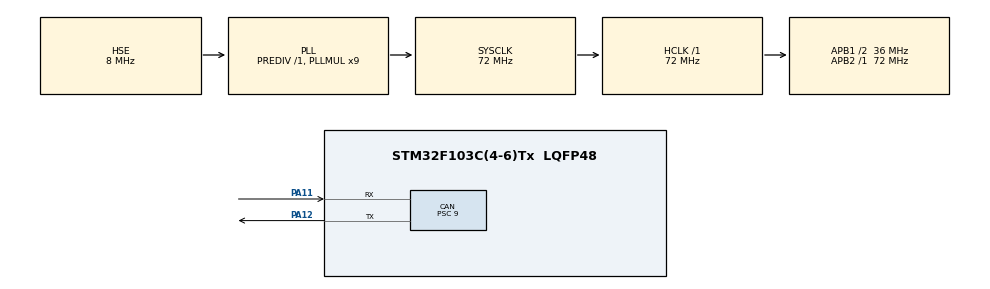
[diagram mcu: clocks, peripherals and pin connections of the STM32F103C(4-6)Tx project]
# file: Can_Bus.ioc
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CAN.ABOM=ENABLE
CAN.BS1=CAN_BS1_5TQ
CAN.BS2=CAN_BS2_2TQ
CAN.CalculateBaudRate=500000
CAN.CalculateTimeBit=2000
CAN.CalculateTimeQuantum=250.0
CAN.NART=ENABLE
CAN.Prescaler=9
Mcu.Family=STM32F1
Mcu.Name=STM32F103C(4-6)Tx
Mcu.Package=LQFP48
NVIC.PriorityGroup=NVIC_PRIORITYGROUP_4
NVIC.USB_LP_CAN1_RX0_IRQn=true\:0\:0\:false\:false\:true\:true\:true\:true
PA11.Mode=CAN_Activate
PA11.Signal=CAN_RX
PA12.Mode=CAN_Activate
PA12.Signal=CAN_TX
PA13.Mode=Serial_Wire
PA13.Signal=SYS_JTMS-SWDIO
PA14.Mode=Serial_Wire
PA14.Signal=SYS_JTCK-SWCLK
PD0-OSC_IN.Mode=HSE-External-Oscillator
PD0-OSC_IN.Signal=RCC_OSC_IN
PD1-OSC_OUT.Mode=HSE-External-Oscillator
PD1-OSC_OUT.Signal=RCC_OSC_OUT
ProjectManager.HeapSize=0x200
ProjectManager.StackSize=0x400
ProjectManager.TargetToolchain=STM32CubeIDE
RCC.AHBFreq_Value=72000000
RCC.APB1CLKDivider=RCC_HCLK_DIV2
RCC.APB1Freq_Value=36000000
RCC.APB1TimFreq_Value=72000000
RCC.APB2Freq_Value=72000000
RCC.APB2TimFreq_Value=72000000
RCC.HCLKFreq_Value=72000000
RCC.PLLMUL=RCC_PLL_MUL9
RCC.PLLSourceVirtual=RCC_PLLSOURCE_HSE
RCC.SYSCLKFreq_VALUE=72000000
RCC.SYSCLKSource=RCC_SYSCLKSOURCE_PLLCLK
RCC.USBFreq_Value=72000000
board=custom

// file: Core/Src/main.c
/* USER CODE BEGIN Header */
/**
  ******************************************************************************
  * @file           : main.c
  * @brief          : Main program body
  ******************************************************************************
  */
/* USER CODE END Header */
#include "main.h"

/* USER CODE BEGIN Includes */
#include "can_lib.h"
/* USER CODE END Includes */

CAN_HandleTypeDef hcan;

void SystemClock_Config(void);
static void MX_GPIO_Init(void);
static void MX_CAN_Init(void);

int main(void)
{

  /* MCU Configuration--------------------------------------------------------*/
  HAL_Init();

  /* Configure the system clock */
  SystemClock_Config();

  /* Initialize all configured peripherals */
  MX_GPIO_Init();
  MX_CAN_Init();

  /* USER CODE BEGIN 2 */
  CAN_Config_Init(&hcan);
  /* USER CODE END 2 */

  /* Infinite loop */
  while (1)
  {

    /* USER CODE BEGIN 3 */
    // Du lieu tu CAN duoc cap nhat tu dong trong callback
    // Xu ly tai day neu can:
    // float acc = can_0x179.acc;
  }
  /* USER CODE END 3 */
}

void SystemClock_Config(void)
{
  RCC_OscInitTypeDef RCC_OscInitStruct = {0};
  RCC_ClkInitTypeDef RCC_ClkInitStruct = {0};

  RCC_OscInitStruct.OscillatorType = RCC_OSCILLATORTYPE_HSE;
  RCC_OscInitStruct.HSEState = RCC_HSE_ON;
  RCC_OscInitStruct.HSEPredivValue = RCC_HSE_PREDIV_DIV1;
  RCC_OscInitStruct.HSIState = RCC_HSI_ON;
  RCC_OscInitStruct.PLL.PLLState = RCC_PLL_ON;
  RCC_OscInitStruct.PLL.PLLSource = RCC_PLLSOURCE_HSE;
  RCC_OscInitStruct.PLL.PLLMUL = RCC_PLL_MUL9;
  if (HAL_RCC_OscConfig(&RCC_OscInitStruct) != HAL_OK)
  {
    Error_Handler();
  }

  RCC_ClkInitStruct.ClockType = RCC_CLOCKTYPE_HCLK|RCC_CLOCKTYPE_SYSCLK
                              |RCC_CLOCKTYPE_PCLK1|RCC_CLOCKTYPE_PCLK2;
  RCC_ClkInitStruct.SYSCLKSource = RCC_SYSCLKSOURCE_PLLCLK;
  RCC_ClkInitStruct.AHBCLKDivider = RCC_SYSCLK_DIV1;
  RCC_ClkInitStruct.APB1CLKDivider = RCC_HCLK_DIV2;
  RCC_ClkInitStruct.APB2CLKDivider = RCC_HCLK_DIV1;

  if (HAL_RCC_ClockConfig(&RCC_ClkInitStruct, FLASH_LATENCY_2) != HAL_OK)
  {
    Error_Handler();
  }
}

static void MX_CAN_Init(void)
{
  hcan.Instance = CAN1;
  hcan.Init.Prescaler = 9;
  hcan.Init.Mode = CAN_MODE_NORMAL;
  hcan.Init.SyncJumpWidth = CAN_SJW_1TQ;
  hcan.Init.TimeSeg1 = CAN_BS1_5TQ;
  hcan.Init.TimeSeg2 = CAN_BS2_2TQ;
  hcan.Init.TimeTriggeredMode = DISABLE;
  hcan.Init.AutoBusOff = ENABLE;
  hcan.Init.AutoWakeUp = DISABLE;
  hcan.Init.AutoRetransmission = ENABLE;
  hcan.Init.ReceiveFifoLocked = DISABLE;
  hcan.Init.TransmitFifoPriority = DISABLE;
  if (HAL_CAN_Init(&hcan) != HAL_OK)
  {
    Error_Handler();
  }
}

static void MX_GPIO_Init(void)
{
  __HAL_RCC_GPIOD_CLK_ENABLE();
  __HAL_RCC_GPIOA_CLK_ENABLE();
}

/* USER CODE BEGIN 4 */
void HAL_CAN_RxFifo0MsgPendingCallback(CAN_HandleTypeDef *hcan)
{
    CAN_RxHeaderTypeDef RxHeader;
    uint8_t RxData[8];

    if (HAL_CAN_GetRxMessage(hcan, CAN_RX_FIFO0, &RxHeader, RxData) == HAL_OK)
    {
        switch (CurrentCarProfile)
        {
            case CAR_VF_LIMO:
                CAN_Decode_Message(RxHeader.StdId, RxData, VF_LIMO_Msg, SIZE_VF_LIMO_Msg, &VF_LIMO_Data);
                /* --- LIMO Logic --- */
                if (VF_LIMO_Data.CreepMode.Disable_Sts == 0) {
                     // Creep ON
                }
                break;

            case CAR_VF789:
                CAN_Decode_Message(RxHeader.StdId, RxData, VF789_Msg, SIZE_VF789_Msg, &VF789_Data);
                /* --- VF789 Logic --- */
                if (VF789_Data.CreepMode.Mode_Req == 1) {
                     // Creep ON
                }
                break;

            default:
                break;
        }
    }
}
/* USER CODE END 4 */

void Error_Handler(void)
{
  __disable_irq();
  while (1)
  {
  }
}
